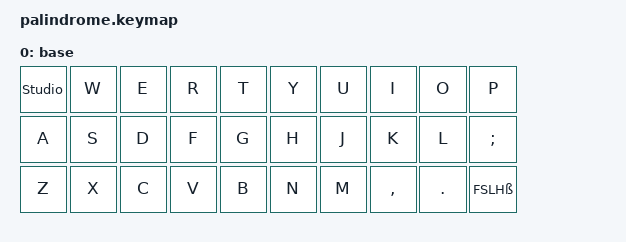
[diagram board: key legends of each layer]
#include <behaviors.dtsi>
#include <dt-bindings/zmk/keys.h>
#include <dt-bindings/zmk/bt.h>
#include <dt-bindings/zmk/outputs.h>

/ {

    keymap {
        compatible = "zmk,keymap";

        base {

            bindings = <
            
            ß&studio_unlock  &kp W  &kp E  &kp R  &kp T &kp Y  &kp U  &kp I     &kp O   &kp P 
            &kp A  &kp S  &kp D  &kp F  &kp G &kp H  &kp J  &kp K     &kp L   &kp SEMI 
            &kp Z  &kp X  &kp C  &kp V  &kp B &kp N  &kp M  &kp COMMA &kp DOT &kp FSLHß
            
            >; 

            sensor-bindings = 
                &inc_dec_kp C_VOL_UP C_VOL_DN
                &inc_dec_kp RIGHT LEFT
            >;
        };
    };
};
